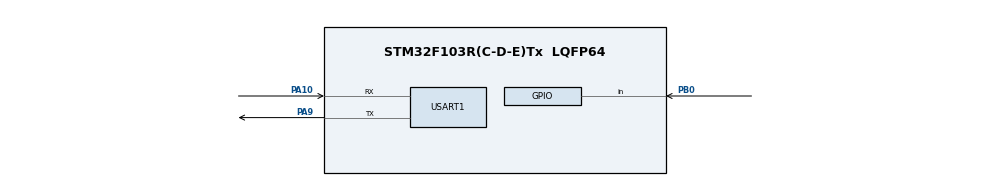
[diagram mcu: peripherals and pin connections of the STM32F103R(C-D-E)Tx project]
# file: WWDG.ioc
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Mcu.Family=STM32F1
Mcu.Name=STM32F103R(C-D-E)Tx
Mcu.Package=LQFP64
NVIC.PriorityGroup=NVIC_PRIORITYGROUP_4
PA10.Mode=Asynchronous
PA10.Signal=USART1_RX
PA13.Mode=JTAG_5_pins
PA13.Signal=SYS_JTMS-SWDIO
PA14.Mode=JTAG_5_pins
PA14.Signal=SYS_JTCK-SWCLK
PA15.Mode=JTAG_5_pins
PA15.Signal=SYS_JTDI
PA9.Mode=Asynchronous
PA9.Signal=USART1_TX
PB0.GPIO_PuPd=GPIO_PULLUP
PB0.Signal=GPIO_Input
PB3.Mode=JTAG_5_pins
PB3.Signal=SYS_JTDO-TRACESWO
PB4.Mode=JTAG_5_pins
PB4.Signal=SYS_NJTRST
PD0-OSC_IN.Mode=HSE-External-Oscillator
PD0-OSC_IN.Signal=RCC_OSC_IN
PD1-OSC_OUT.Mode=HSE-External-Oscillator
PD1-OSC_OUT.Signal=RCC_OSC_OUT
ProjectManager.HeapSize=0x200
ProjectManager.StackSize=0x400
ProjectManager.TargetToolchain=MDK-ARM V5.27
RCC.AHBFreq_Value=8000000
RCC.APB1Freq_Value=8000000
RCC.APB1TimFreq_Value=8000000
RCC.APB2Freq_Value=8000000
RCC.APB2TimFreq_Value=8000000
RCC.HCLKFreq_Value=8000000
USART1.VirtualMode=VM_ASYNC
VP_WWDG_VS_WWDG.Mode=WWDG_Activate
WWDG.Counter=127
WWDG.Prescaler=WWDG_PRESCALER_8
WWDG.Window=90
board=custom

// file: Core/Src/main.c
/* USER CODE BEGIN Header */
/**
  ******************************************************************************
  * @file           : main.c
  * @brief          : Main program body
  ******************************************************************************
  * @attention
  *
  * <h2><center>&copy; Copyright (c) 2021 STMicroelectronics.
  * All rights reserved.</center></h2>
  *
  * This software component is licensed by ST under BSD 3-Clause license,
  * the "License"; You may not use this file except in compliance with the
  * License. You may obtain a copy of the License at:
  *                        opensource.org/licenses/BSD-3-Clause
  *
  ******************************************************************************
  */
/* USER CODE END Header */
#include "main.h"

/* USER CODE BEGIN Includes */
#include "stdio.h"
#include "show_all_reset_sources.h"
#include "stdio_usart1.h"
/* USER CODE END Includes */

void SystemClock_Config(void);
static void MX_GPIO_Init(void);
static void MX_WWDG_Init(void);
static void MX_USART1_UART_Init(void);

int main(void)
{

  /* MCU Configuration--------------------------------------------------------*/

  /* Reset of all peripherals, Initializes the Flash interface and the Systick. */

  LL_APB2_GRP1_EnableClock(LL_APB2_GRP1_PERIPH_AFIO);
  LL_APB1_GRP1_EnableClock(LL_APB1_GRP1_PERIPH_PWR);

  NVIC_SetPriorityGrouping(NVIC_PRIORITYGROUP_4);

  /* System interrupt init*/

  /** ENABLE: Full SWJ (JTAG-DP + SW-DP): Reset State
  */
  LL_GPIO_AF_EnableRemap_SWJ();

  /* Configure the system clock */
  SystemClock_Config();

  /* Initialize all configured peripherals */
  MX_GPIO_Init();
  MX_WWDG_Init();
  MX_USART1_UART_Init();
  /* USER CODE BEGIN 2 */
	uint32_t i, count = 0;									//test counters
	show_reset_sources();										//to print sources of reset

  /* USER CODE END 2 */

  /* Infinite loop */
  while (1)
  {

    /* USER CODE BEGIN 3 */

		/* printing the counter nearly every second */
		i++;
		if(i > 500000)
		{
			count++;
			i = 0;
			printf("count is: %d\r\n", count);
		}

		/* if push button connected to PB0 is pushed, then the WWDG counter wont be reset */
		if(((LL_GPIO_ReadInputPort(GPIOB)) & (1<<0)) != 0)
		{
				if(LL_WWDG_GetCounter(WWDG) < 91)
				{
					LL_WWDG_SetCounter(WWDG, 127);
				}
		}

  }
  /* USER CODE END 3 */
}

void SystemClock_Config(void)
{
  LL_FLASH_SetLatency(LL_FLASH_LATENCY_0);
  while(LL_FLASH_GetLatency()!= LL_FLASH_LATENCY_0)
  {
  }
  LL_RCC_HSI_SetCalibTrimming(16);
  LL_RCC_HSI_Enable();

   /* Wait till HSI is ready */
  while(LL_RCC_HSI_IsReady() != 1)
  {

  }
  LL_RCC_SetAHBPrescaler(LL_RCC_SYSCLK_DIV_1);
  LL_RCC_SetAPB1Prescaler(LL_RCC_APB1_DIV_1);
  LL_RCC_SetAPB2Prescaler(LL_RCC_APB2_DIV_1);
  LL_RCC_SetSysClkSource(LL_RCC_SYS_CLKSOURCE_HSI);

   /* Wait till System clock is ready */
  while(LL_RCC_GetSysClkSource() != LL_RCC_SYS_CLKSOURCE_STATUS_HSI)
  {

  }
  LL_Init1msTick(8000000);
  LL_SetSystemCoreClock(8000000);
}

static void MX_USART1_UART_Init(void)
{

  LL_USART_InitTypeDef USART_InitStruct = {0};

  LL_GPIO_InitTypeDef GPIO_InitStruct = {0};

  /* Peripheral clock enable */
  LL_APB2_GRP1_EnableClock(LL_APB2_GRP1_PERIPH_USART1);

  LL_APB2_GRP1_EnableClock(LL_APB2_GRP1_PERIPH_GPIOA);
  /**USART1 GPIO Configuration
  PA9   ------> USART1_TX
  PA10   ------> USART1_RX
  */
  GPIO_InitStruct.Pin = LL_GPIO_PIN_9;
  GPIO_InitStruct.Mode = LL_GPIO_MODE_ALTERNATE;
  GPIO_InitStruct.Speed = LL_GPIO_SPEED_FREQ_HIGH;
  GPIO_InitStruct.OutputType = LL_GPIO_OUTPUT_PUSHPULL;
  LL_GPIO_Init(GPIOA, &GPIO_InitStruct);

  GPIO_InitStruct.Pin = LL_GPIO_PIN_10;
  GPIO_InitStruct.Mode = LL_GPIO_MODE_FLOATING;
  LL_GPIO_Init(GPIOA, &GPIO_InitStruct);

  USART_InitStruct.BaudRate = 115200;
  USART_InitStruct.DataWidth = LL_USART_DATAWIDTH_8B;
  USART_InitStruct.StopBits = LL_USART_STOPBITS_1;
  USART_InitStruct.Parity = LL_USART_PARITY_NONE;
  USART_InitStruct.TransferDirection = LL_USART_DIRECTION_TX_RX;
  USART_InitStruct.HardwareFlowControl = LL_USART_HWCONTROL_NONE;
  USART_InitStruct.OverSampling = LL_USART_OVERSAMPLING_16;
  LL_USART_Init(USART1, &USART_InitStruct);
  LL_USART_ConfigAsyncMode(USART1);
  LL_USART_Enable(USART1);

}

static void MX_WWDG_Init(void)
{

  /* Peripheral clock enable */
  LL_APB1_GRP1_EnableClock(LL_APB1_GRP1_PERIPH_WWDG);

  LL_WWDG_SetCounter(WWDG, 127);
  LL_WWDG_Enable(WWDG);
  LL_WWDG_SetPrescaler(WWDG, LL_WWDG_PRESCALER_8);
  LL_WWDG_SetWindow(WWDG, 90);

}

static void MX_GPIO_Init(void)
{
  LL_GPIO_InitTypeDef GPIO_InitStruct = {0};

  /* GPIO Ports Clock Enable */
  LL_APB2_GRP1_EnableClock(LL_APB2_GRP1_PERIPH_GPIOD);
  LL_APB2_GRP1_EnableClock(LL_APB2_GRP1_PERIPH_GPIOB);
  LL_APB2_GRP1_EnableClock(LL_APB2_GRP1_PERIPH_GPIOA);

  /**/
  GPIO_InitStruct.Pin = LL_GPIO_PIN_0;
  GPIO_InitStruct.Mode = LL_GPIO_MODE_INPUT;
  GPIO_InitStruct.Pull = LL_GPIO_PULL_UP;
  LL_GPIO_Init(GPIOB, &GPIO_InitStruct);

}

void Error_Handler(void)
{
  __disable_irq();
  while (1)
  {
  }
}

/************************ (C) COPYRIGHT STMicroelectronics *****END OF FILE****/
